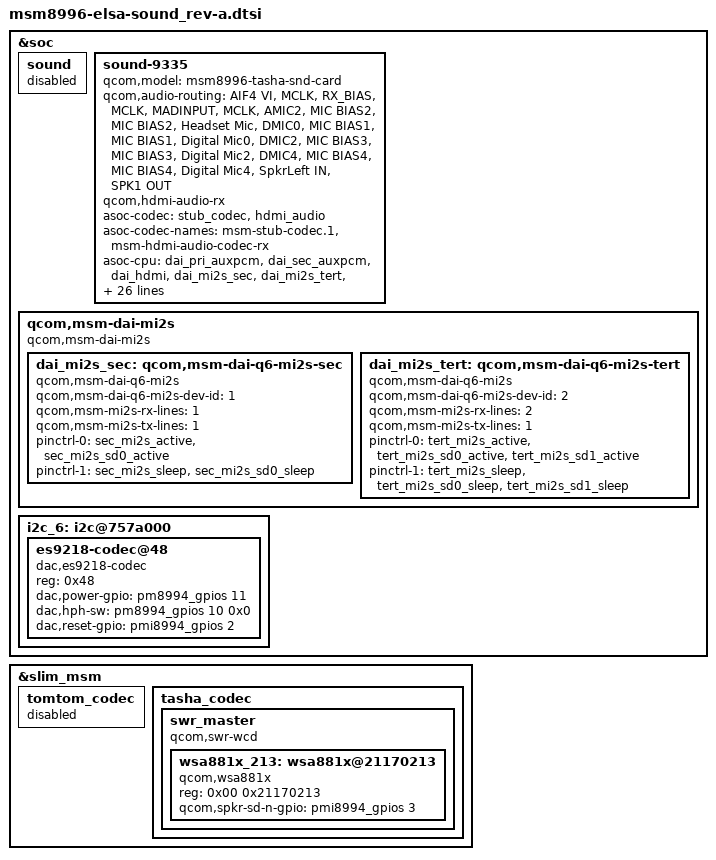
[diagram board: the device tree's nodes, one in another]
/* Copyright (c) 2015, The Linux Foundation. All rights reserved.
 *
 * This program is free software; you can redistribute it and/or modify
 * it under the terms of the GNU General Public License version 2 and
 * only version 2 as published by the Free Software Foundation.
 *
 * This program is distributed in the hope that it will be useful,
 * but WITHOUT ANY WARRANTY; without even the implied warranty of
 * MERCHANTABILITY or FITNESS FOR A PARTICULAR PURPOSE.  See the
 * GNU General Public License for more details.
 */

&soc {

	sound {
		status = "disabled";
	};

	sound-9335 {
		qcom,model = "msm8996-tasha-snd-card";

		qcom,audio-routing =
			"AIF4 VI", "MCLK",
			"RX_BIAS", "MCLK",
			"MADINPUT", "MCLK",
			"AMIC2", "MIC BIAS2",
			"MIC BIAS2", "Headset Mic",
			"DMIC0", "MIC BIAS1",
			"MIC BIAS1", "Digital Mic0",
			"DMIC2", "MIC BIAS3",
			"MIC BIAS3", "Digital Mic2",
			"DMIC4", "MIC BIAS4",
			"MIC BIAS4", "Digital Mic4",
			"SpkrLeft IN", "SPK1 OUT";

		qcom,hdmi-audio-rx;
		asoc-codec = <&stub_codec>, <&hdmi_audio>;
		asoc-codec-names = "msm-stub-codec.1", "msm-hdmi-audio-codec-rx";
		asoc-cpu = <&dai_pri_auxpcm>, <&dai_sec_auxpcm>, <&dai_hdmi>, <&dai_mi2s_sec>, <&dai_mi2s_tert>,
			<&sb_0_rx>, <&sb_0_tx>, <&sb_1_rx>, <&sb_1_tx>,
			<&sb_2_rx>, <&sb_2_tx>, <&sb_3_rx>, <&sb_3_tx>,
			<&sb_4_rx>, <&sb_4_tx>, <&sb_5_tx>, <&afe_pcm_rx>,
			<&afe_pcm_tx>, <&afe_proxy_rx>, <&afe_proxy_tx>,
			<&incall_record_rx>, <&incall_record_tx>,
			<&incall_music_rx>, <&incall_music2_rx>,
			<&sb_5_rx>, <&sb_6_rx>;
		asoc-cpu-names = "msm-dai-q6-auxpcm.1", "msm-dai-q6-auxpcm.2",
			"msm-dai-q6-hdmi.8", "msm-dai-q6-mi2s.1","msm-dai-q6-mi2s.2",
			"msm-dai-q6-dev.16384", "msm-dai-q6-dev.16385",
			"msm-dai-q6-dev.16386", "msm-dai-q6-dev.16387",
			"msm-dai-q6-dev.16388", "msm-dai-q6-dev.16389",
			"msm-dai-q6-dev.16390", "msm-dai-q6-dev.16391",
			"msm-dai-q6-dev.16392", "msm-dai-q6-dev.16393",
			"msm-dai-q6-dev.16395", "msm-dai-q6-dev.224",
			"msm-dai-q6-dev.225", "msm-dai-q6-dev.241",
			"msm-dai-q6-dev.240", "msm-dai-q6-dev.32771",
			"msm-dai-q6-dev.32772", "msm-dai-q6-dev.32773",
			"msm-dai-q6-dev.32770", "msm-dai-q6-dev.16394",
			"msm-dai-q6-dev.16396";
		qcom,wsa-max-devs = <1>;
		qcom,wsa-devs = <&wsa881x_213>;
		qcom,wsa-aux-dev-prefix = "SpkrLeft";
		qcom,msm-mbhc-hphl-swh = <1>;
		qcom,mbhc-audio-jack-type = "4-pole-jack";
	};

	qcom,msm-dai-mi2s {
		compatible = "qcom,msm-dai-mi2s";
		dai_mi2s_sec: qcom,msm-dai-q6-mi2s-sec {
			compatible = "qcom,msm-dai-q6-mi2s";
			qcom,msm-dai-q6-mi2s-dev-id = <1>;
			qcom,msm-mi2s-rx-lines = <1>;
			qcom,msm-mi2s-tx-lines = <1>;
			pinctrl-names = "default", "idle";
			pinctrl-0 = <&sec_mi2s_active &sec_mi2s_sd0_active>;
			pinctrl-1 = <&sec_mi2s_sleep &sec_mi2s_sd0_sleep>;
		};

		dai_mi2s_tert: qcom,msm-dai-q6-mi2s-tert {
			compatible = "qcom,msm-dai-q6-mi2s";
			qcom,msm-dai-q6-mi2s-dev-id = <2>;
			qcom,msm-mi2s-rx-lines = <2>;
			qcom,msm-mi2s-tx-lines = <1>;
			pinctrl-names = "default", "idle";
			pinctrl-0 = <&tert_mi2s_active &tert_mi2s_sd0_active &tert_mi2s_sd1_active>;
			pinctrl-1 = <&tert_mi2s_sleep &tert_mi2s_sd0_sleep &tert_mi2s_sd1_sleep>;
		};
	};

	i2c_6: i2c@757a000 {
		es9218-codec@48 {
			compatible = "dac,es9218-codec";
			status = "ok";
			reg = <0x48>;
			dac,power-gpio = <&pm8994_gpios 11 0x0>;
			dac,hph-sw = <&pm8994_gpios 10 0x0>;
			dac,reset-gpio = <&pmi8994_gpios 2 0x0>;
		};
	};
};

&slim_msm {
	tomtom_codec {
		status = "disabled";
	};
	tasha_codec {
		swr_master {
			compatible = "qcom,swr-wcd";
			#address-cells = <2>;
			#size-cells = <0>;

			wsa881x_213: wsa881x@21170213 {
				compatible = "qcom,wsa881x";
				reg = <0x00 0x21170213>;
				qcom,spkr-sd-n-gpio = <&pmi8994_gpios 3 0>;
			};
		};
	};
};
